# ESP32-C3 register map
Vendor: ESPRESSIF SYSTEMS (SHANGHAI) CO., LTD.; Series: ESP32 C-Series; File version: 19
CPU: RV32IMC r0p0, little endian, no MPU, no FPU, 0 interrupt priority bits
Address unit: 32 bits
Registers are 32-bit, read-write, reset 0x0 unless marked. A register's access mark holds for its fields unless they carry their own. Offsets are from the block's base; [hi:lo] are bit positions; {n}, {i} and the like mark numbered series.

## SENSITIVE — SENSITIVE Peripheral
Base 0x600C1000
0x00 ROM_TABLE_LOCK — SENSITIVE_ROM_TABLE_LOCK_REG
  [0] ROM_TABLE_LOCK
0x04 ROM_TABLE — SENSITIVE_ROM_TABLE_REG
0x08 PRIVILEGE_MODE_SEL_LOCK — SENSITIVE_PRIVILEGE_MODE_SEL_LOCK_REG
  [0] PRIVILEGE_MODE_SEL_LOCK
0x0C PRIVILEGE_MODE_SEL — SENSITIVE_PRIVILEGE_MODE_SEL_REG
  [0] PRIVILEGE_MODE_SEL
0x10 APB_PERIPHERAL_ACCESS_0 — SENSITIVE_APB_PERIPHERAL_ACCESS_0_REG
  [0] APB_PERIPHERAL_ACCESS_LOCK
0x14 APB_PERIPHERAL_ACCESS_1 reset 0x1 — SENSITIVE_APB_PERIPHERAL_ACCESS_1_REG
  [0] APB_PERIPHERAL_ACCESS_SPLIT_BURST
0x18 INTERNAL_SRAM_USAGE_0 — SENSITIVE_INTERNAL_SRAM_USAGE_0_REG
  [0] INTERNAL_SRAM_USAGE_LOCK
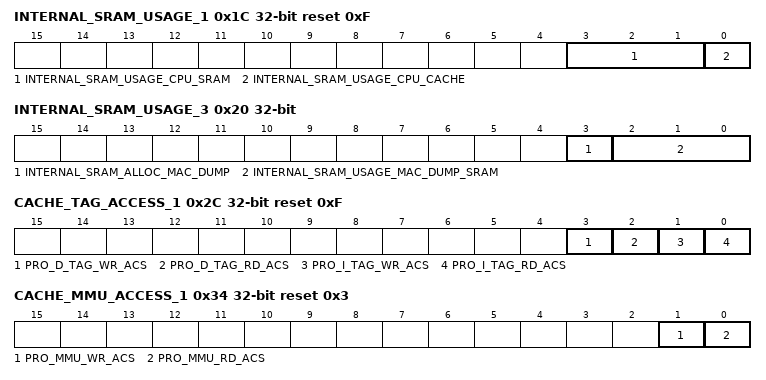
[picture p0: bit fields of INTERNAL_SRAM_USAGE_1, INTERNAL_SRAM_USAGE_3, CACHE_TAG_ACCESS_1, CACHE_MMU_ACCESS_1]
0x1C INTERNAL_SRAM_USAGE_1 reset 0xF — SENSITIVE_INTERNAL_SRAM_USAGE_1_REG
  [3:1] INTERNAL_SRAM_USAGE_CPU_SRAM, [0] INTERNAL_SRAM_USAGE_CPU_CACHE
0x20 INTERNAL_SRAM_USAGE_3 — SENSITIVE_INTERNAL_SRAM_USAGE_3_REG
  [3] INTERNAL_SRAM_ALLOC_MAC_DUMP, [2:0] INTERNAL_SRAM_USAGE_MAC_DUMP_SRAM
0x24 INTERNAL_SRAM_USAGE_4 — SENSITIVE_INTERNAL_SRAM_USAGE_4_REG
  [0] INTERNAL_SRAM_USAGE_LOG_SRAM
0x28 CACHE_TAG_ACCESS_0 — SENSITIVE_CACHE_TAG_ACCESS_0_REG
  [0] CACHE_TAG_ACCESS_LOCK
0x2C CACHE_TAG_ACCESS_1 reset 0xF — SENSITIVE_CACHE_TAG_ACCESS_1_REG
  [3] PRO_D_TAG_WR_ACS, [2] PRO_D_TAG_RD_ACS, [1] PRO_I_TAG_WR_ACS, [0] PRO_I_TAG_RD_ACS
0x30 CACHE_MMU_ACCESS_0 — SENSITIVE_CACHE_MMU_ACCESS_0_REG
  [0] CACHE_MMU_ACCESS_LOCK
0x34 CACHE_MMU_ACCESS_1 reset 0x3 — SENSITIVE_CACHE_MMU_ACCESS_1_REG
  [1] PRO_MMU_WR_ACS, [0] PRO_MMU_RD_ACS
0x38 DMA_APBPERI_SPI2_PMS_CONSTRAIN_0 — SENSITIVE_DMA_APBPERI_SPI2_PMS_CONSTRAIN_0_REG
  [0] DMA_APBPERI_SPI2_PMS_CONSTRAIN_LOCK
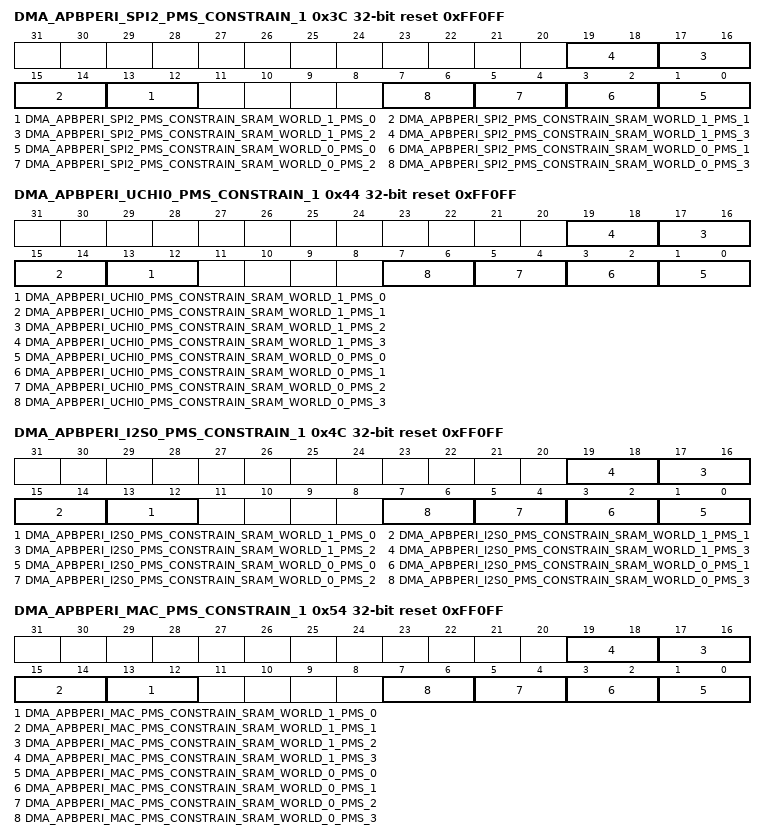
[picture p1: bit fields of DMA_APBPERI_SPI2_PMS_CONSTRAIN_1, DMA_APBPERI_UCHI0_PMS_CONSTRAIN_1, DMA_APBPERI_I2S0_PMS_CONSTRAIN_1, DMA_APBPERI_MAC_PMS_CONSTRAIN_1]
0x3C DMA_APBPERI_SPI2_PMS_CONSTRAIN_1 reset 0xFF0FF — SENSITIVE_DMA_APBPERI_SPI2_PMS_CONSTRAIN_1_REG
  [2n+13:2n+12] DMA_APBPERI_SPI2_PMS_CONSTRAIN_SRAM_WORLD_1_PMS_{n} (n=0..3), [2n+1:2n] DMA_APBPERI_SPI2_PMS_CONSTRAIN_SRAM_WORLD_0_PMS_{n} (n=0..3)
0x40 DMA_APBPERI_UCHI0_PMS_CONSTRAIN_0 — SENSITIVE_DMA_APBPERI_UCHI0_PMS_CONSTRAIN_0_REG
  [0] DMA_APBPERI_UCHI0_PMS_CONSTRAIN_LOCK
0x44 DMA_APBPERI_UCHI0_PMS_CONSTRAIN_1 reset 0xFF0FF — SENSITIVE_DMA_APBPERI_UCHI0_PMS_CONSTRAIN_1_REG
  [2n+13:2n+12] DMA_APBPERI_UCHI0_PMS_CONSTRAIN_SRAM_WORLD_1_PMS_{n} (n=0..3), [2n+1:2n] DMA_APBPERI_UCHI0_PMS_CONSTRAIN_SRAM_WORLD_0_PMS_{n} (n=0..3)
0x48 DMA_APBPERI_I2S0_PMS_CONSTRAIN_0 — SENSITIVE_DMA_APBPERI_I2S0_PMS_CONSTRAIN_0_REG
  [0] DMA_APBPERI_I2S0_PMS_CONSTRAIN_LOCK
0x4C DMA_APBPERI_I2S0_PMS_CONSTRAIN_1 reset 0xFF0FF — SENSITIVE_DMA_APBPERI_I2S0_PMS_CONSTRAIN_1_REG
  [2n+13:2n+12] DMA_APBPERI_I2S0_PMS_CONSTRAIN_SRAM_WORLD_1_PMS_{n} (n=0..3), [2n+1:2n] DMA_APBPERI_I2S0_PMS_CONSTRAIN_SRAM_WORLD_0_PMS_{n} (n=0..3)
0x50 DMA_APBPERI_MAC_PMS_CONSTRAIN_0 — SENSITIVE_DMA_APBPERI_MAC_PMS_CONSTRAIN_0_REG
  [0] DMA_APBPERI_MAC_PMS_CONSTRAIN_LOCK
0x54 DMA_APBPERI_MAC_PMS_CONSTRAIN_1 reset 0xFF0FF — SENSITIVE_DMA_APBPERI_MAC_PMS_CONSTRAIN_1_REG
  [2n+13:2n+12] DMA_APBPERI_MAC_PMS_CONSTRAIN_SRAM_WORLD_1_PMS_{n} (n=0..3), [2n+1:2n] DMA_APBPERI_MAC_PMS_CONSTRAIN_SRAM_WORLD_0_PMS_{n} (n=0..3)
0x58 DMA_APBPERI_BACKUP_PMS_CONSTRAIN_0 — SENSITIVE_DMA_APBPERI_BACKUP_PMS_CONSTRAIN_0_REG
  [0] DMA_APBPERI_BACKUP_PMS_CONSTRAIN_LOCK
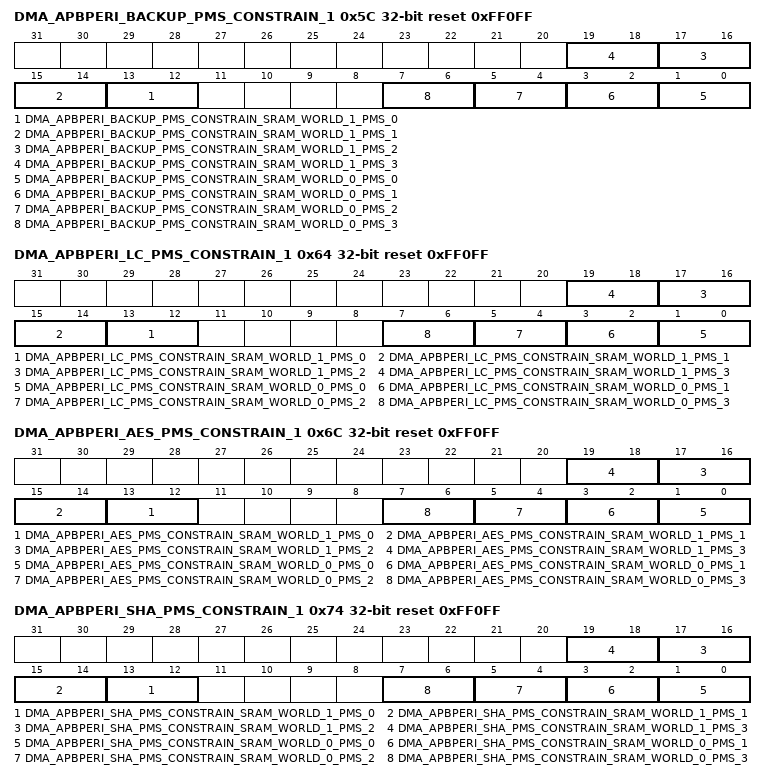
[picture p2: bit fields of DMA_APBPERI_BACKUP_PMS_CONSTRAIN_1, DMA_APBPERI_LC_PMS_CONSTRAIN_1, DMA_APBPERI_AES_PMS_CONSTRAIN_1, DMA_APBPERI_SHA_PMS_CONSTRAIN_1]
0x5C DMA_APBPERI_BACKUP_PMS_CONSTRAIN_1 reset 0xFF0FF — SENSITIVE_DMA_APBPERI_BACKUP_PMS_CONSTRAIN_1_REG
  [2n+13:2n+12] DMA_APBPERI_BACKUP_PMS_CONSTRAIN_SRAM_WORLD_1_PMS_{n} (n=0..3), [2n+1:2n] DMA_APBPERI_BACKUP_PMS_CONSTRAIN_SRAM_WORLD_0_PMS_{n} (n=0..3)
0x60 DMA_APBPERI_LC_PMS_CONSTRAIN_0 — SENSITIVE_DMA_APBPERI_LC_PMS_CONSTRAIN_0_REG
  [0] DMA_APBPERI_LC_PMS_CONSTRAIN_LOCK
0x64 DMA_APBPERI_LC_PMS_CONSTRAIN_1 reset 0xFF0FF — SENSITIVE_DMA_APBPERI_LC_PMS_CONSTRAIN_1_REG
  [2n+13:2n+12] DMA_APBPERI_LC_PMS_CONSTRAIN_SRAM_WORLD_1_PMS_{n} (n=0..3), [2n+1:2n] DMA_APBPERI_LC_PMS_CONSTRAIN_SRAM_WORLD_0_PMS_{n} (n=0..3)
0x68 DMA_APBPERI_AES_PMS_CONSTRAIN_0 — SENSITIVE_DMA_APBPERI_AES_PMS_CONSTRAIN_0_REG
  [0] DMA_APBPERI_AES_PMS_CONSTRAIN_LOCK
0x6C DMA_APBPERI_AES_PMS_CONSTRAIN_1 reset 0xFF0FF — SENSITIVE_DMA_APBPERI_AES_PMS_CONSTRAIN_1_REG
  [2n+13:2n+12] DMA_APBPERI_AES_PMS_CONSTRAIN_SRAM_WORLD_1_PMS_{n} (n=0..3), [2n+1:2n] DMA_APBPERI_AES_PMS_CONSTRAIN_SRAM_WORLD_0_PMS_{n} (n=0..3)
0x70 DMA_APBPERI_SHA_PMS_CONSTRAIN_0 — SENSITIVE_DMA_APBPERI_SHA_PMS_CONSTRAIN_0_REG
  [0] DMA_APBPERI_SHA_PMS_CONSTRAIN_LOCK
0x74 DMA_APBPERI_SHA_PMS_CONSTRAIN_1 reset 0xFF0FF — SENSITIVE_DMA_APBPERI_SHA_PMS_CONSTRAIN_1_REG
  [2n+13:2n+12] DMA_APBPERI_SHA_PMS_CONSTRAIN_SRAM_WORLD_1_PMS_{n} (n=0..3), [2n+1:2n] DMA_APBPERI_SHA_PMS_CONSTRAIN_SRAM_WORLD_0_PMS_{n} (n=0..3)
0x78 DMA_APBPERI_ADC_DAC_PMS_CONSTRAIN_0 — SENSITIVE_DMA_APBPERI_ADC_DAC_PMS_CONSTRAIN_0_REG
  [0] DMA_APBPERI_ADC_DAC_PMS_CONSTRAIN_LOCK
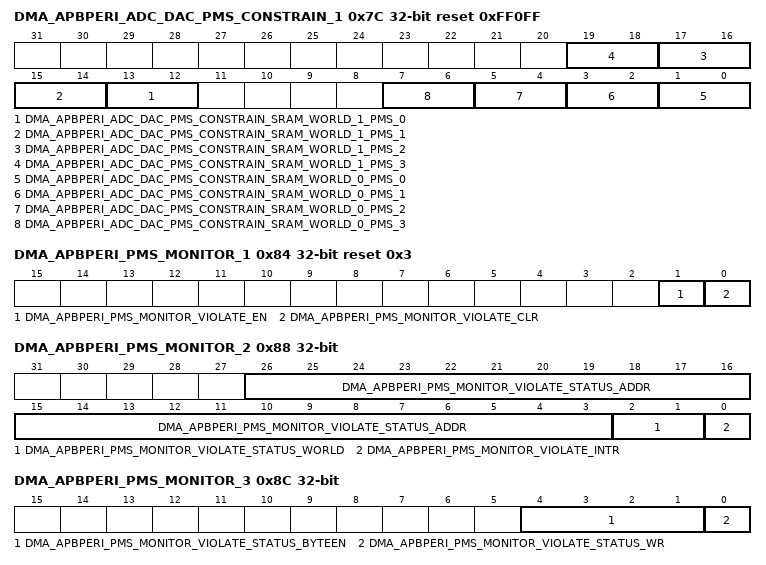
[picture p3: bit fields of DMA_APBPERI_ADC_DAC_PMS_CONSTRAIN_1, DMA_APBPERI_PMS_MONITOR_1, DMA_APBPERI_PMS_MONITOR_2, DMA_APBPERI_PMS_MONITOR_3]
0x7C DMA_APBPERI_ADC_DAC_PMS_CONSTRAIN_1 reset 0xFF0FF — SENSITIVE_DMA_APBPERI_ADC_DAC_PMS_CONSTRAIN_1_REG
  [2n+13:2n+12] DMA_APBPERI_ADC_DAC_PMS_CONSTRAIN_SRAM_WORLD_1_PMS_{n} (n=0..3), [2n+1:2n] DMA_APBPERI_ADC_DAC_PMS_CONSTRAIN_SRAM_WORLD_0_PMS_{n} (n=0..3)
0x80 DMA_APBPERI_PMS_MONITOR_0 — SENSITIVE_DMA_APBPERI_PMS_MONITOR_0_REG
  [0] DMA_APBPERI_PMS_MONITOR_LOCK
0x84 DMA_APBPERI_PMS_MONITOR_1 reset 0x3 — SENSITIVE_DMA_APBPERI_PMS_MONITOR_1_REG
  [1] DMA_APBPERI_PMS_MONITOR_VIOLATE_EN, [0] DMA_APBPERI_PMS_MONITOR_VIOLATE_CLR
0x88 DMA_APBPERI_PMS_MONITOR_2 ro — SENSITIVE_DMA_APBPERI_PMS_MONITOR_2_REG
  [26:3] DMA_APBPERI_PMS_MONITOR_VIOLATE_STATUS_ADDR, [2:1] DMA_APBPERI_PMS_MONITOR_VIOLATE_STATUS_WORLD, [0] DMA_APBPERI_PMS_MONITOR_VIOLATE_INTR
0x8C DMA_APBPERI_PMS_MONITOR_3 ro — SENSITIVE_DMA_APBPERI_PMS_MONITOR_3_REG
  [4:1] DMA_APBPERI_PMS_MONITOR_VIOLATE_STATUS_BYTEEN, [0] DMA_APBPERI_PMS_MONITOR_VIOLATE_STATUS_WR
0x90 CORE_X_IRAM0_DRAM0_DMA_SPLIT_LINE_CONSTRAIN_0 — SENSITIVE_CORE_X_IRAM0_DRAM0_DMA_SPLIT_LINE_CONSTRAIN_0_REG
  [0] CORE_X_IRAM0_DRAM0_DMA_SPLIT_LINE_CONSTRAIN_LOCK
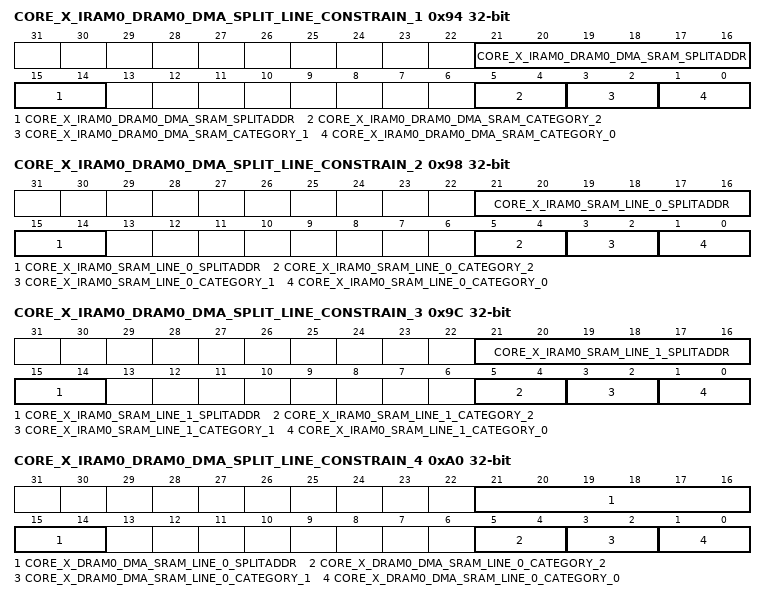
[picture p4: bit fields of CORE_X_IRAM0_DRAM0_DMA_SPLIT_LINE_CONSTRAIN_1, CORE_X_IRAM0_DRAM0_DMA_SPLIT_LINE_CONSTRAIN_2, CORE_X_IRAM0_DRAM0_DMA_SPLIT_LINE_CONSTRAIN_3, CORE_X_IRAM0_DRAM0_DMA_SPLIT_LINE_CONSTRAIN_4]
0x94 CORE_X_IRAM0_DRAM0_DMA_SPLIT_LINE_CONSTRAIN_1 — SENSITIVE_CORE_X_IRAM0_DRAM0_DMA_SPLIT_LINE_CONSTRAIN_1_REG
  [21:14] CORE_X_IRAM0_DRAM0_DMA_SRAM_SPLITADDR, [5:4] CORE_X_IRAM0_DRAM0_DMA_SRAM_CATEGORY_2, [3:2] CORE_X_IRAM0_DRAM0_DMA_SRAM_CATEGORY_1, [1:0] CORE_X_IRAM0_DRAM0_DMA_SRAM_CATEGORY_0
0x98 CORE_X_IRAM0_DRAM0_DMA_SPLIT_LINE_CONSTRAIN_2 — SENSITIVE_CORE_X_IRAM0_DRAM0_DMA_SPLIT_LINE_CONSTRAIN_2_REG
  [21:14] CORE_X_IRAM0_SRAM_LINE_0_SPLITADDR, [5:4] CORE_X_IRAM0_SRAM_LINE_0_CATEGORY_2, [3:2] CORE_X_IRAM0_SRAM_LINE_0_CATEGORY_1, [1:0] CORE_X_IRAM0_SRAM_LINE_0_CATEGORY_0
0x9C CORE_X_IRAM0_DRAM0_DMA_SPLIT_LINE_CONSTRAIN_3 — SENSITIVE_CORE_X_IRAM0_DRAM0_DMA_SPLIT_LINE_CONSTRAIN_3_REG
  [21:14] CORE_X_IRAM0_SRAM_LINE_1_SPLITADDR, [5:4] CORE_X_IRAM0_SRAM_LINE_1_CATEGORY_2, [3:2] CORE_X_IRAM0_SRAM_LINE_1_CATEGORY_1, [1:0] CORE_X_IRAM0_SRAM_LINE_1_CATEGORY_0
0xA0 CORE_X_IRAM0_DRAM0_DMA_SPLIT_LINE_CONSTRAIN_4 — SENSITIVE_CORE_X_IRAM0_DRAM0_DMA_SPLIT_LINE_CONSTRAIN_4_REG
  [21:14] CORE_X_DRAM0_DMA_SRAM_LINE_0_SPLITADDR, [5:4] CORE_X_DRAM0_DMA_SRAM_LINE_0_CATEGORY_2, [3:2] CORE_X_DRAM0_DMA_SRAM_LINE_0_CATEGORY_1, [1:0] CORE_X_DRAM0_DMA_SRAM_LINE_0_CATEGORY_0
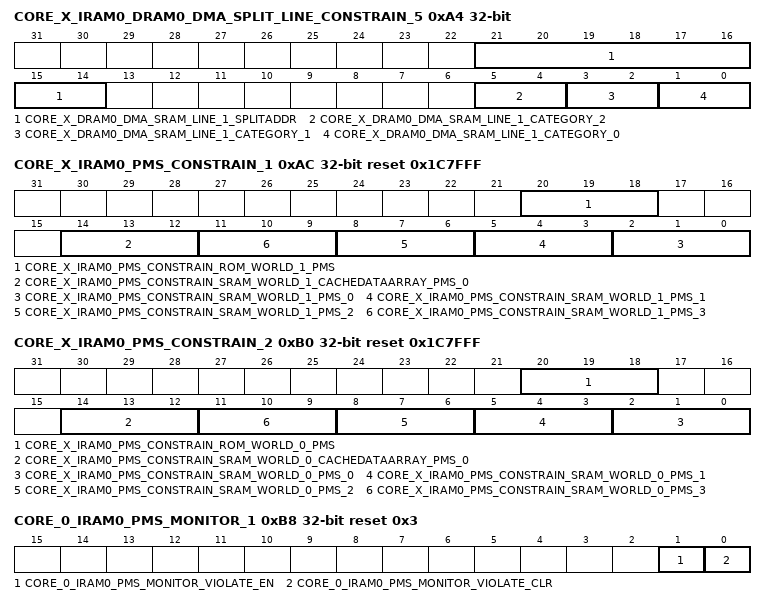
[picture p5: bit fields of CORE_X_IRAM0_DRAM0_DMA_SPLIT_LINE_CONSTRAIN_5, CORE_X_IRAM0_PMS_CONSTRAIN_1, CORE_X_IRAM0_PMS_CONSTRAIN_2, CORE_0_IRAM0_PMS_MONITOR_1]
0xA4 CORE_X_IRAM0_DRAM0_DMA_SPLIT_LINE_CONSTRAIN_5 — SENSITIVE_CORE_X_IRAM0_DRAM0_DMA_SPLIT_LINE_CONSTRAIN_5_REG
  [21:14] CORE_X_DRAM0_DMA_SRAM_LINE_1_SPLITADDR, [5:4] CORE_X_DRAM0_DMA_SRAM_LINE_1_CATEGORY_2, [3:2] CORE_X_DRAM0_DMA_SRAM_LINE_1_CATEGORY_1, [1:0] CORE_X_DRAM0_DMA_SRAM_LINE_1_CATEGORY_0
0xA8 CORE_X_IRAM0_PMS_CONSTRAIN_0 — SENSITIVE_CORE_X_IRAM0_PMS_CONSTRAIN_0_REG
  [0] CORE_X_IRAM0_PMS_CONSTRAIN_LOCK
0xAC CORE_X_IRAM0_PMS_CONSTRAIN_1 reset 0x1C7FFF — SENSITIVE_CORE_X_IRAM0_PMS_CONSTRAIN_1_REG
  [20:18] CORE_X_IRAM0_PMS_CONSTRAIN_ROM_WORLD_1_PMS, [14:12] CORE_X_IRAM0_PMS_CONSTRAIN_SRAM_WORLD_1_CACHEDATAARRAY_PMS_0, [3n+2:3n] CORE_X_IRAM0_PMS_CONSTRAIN_SRAM_WORLD_1_PMS_{n} (n=0..3)
0xB0 CORE_X_IRAM0_PMS_CONSTRAIN_2 reset 0x1C7FFF — SENSITIVE_CORE_X_IRAM0_PMS_CONSTRAIN_2_REG
  [20:18] CORE_X_IRAM0_PMS_CONSTRAIN_ROM_WORLD_0_PMS, [14:12] CORE_X_IRAM0_PMS_CONSTRAIN_SRAM_WORLD_0_CACHEDATAARRAY_PMS_0, [3n+2:3n] CORE_X_IRAM0_PMS_CONSTRAIN_SRAM_WORLD_0_PMS_{n} (n=0..3)
0xB4 CORE_0_IRAM0_PMS_MONITOR_0 — SENSITIVE_CORE_0_IRAM0_PMS_MONITOR_0_REG
  [0] CORE_0_IRAM0_PMS_MONITOR_LOCK
0xB8 CORE_0_IRAM0_PMS_MONITOR_1 reset 0x3 — SENSITIVE_CORE_0_IRAM0_PMS_MONITOR_1_REG
  [1] CORE_0_IRAM0_PMS_MONITOR_VIOLATE_EN, [0] CORE_0_IRAM0_PMS_MONITOR_VIOLATE_CLR
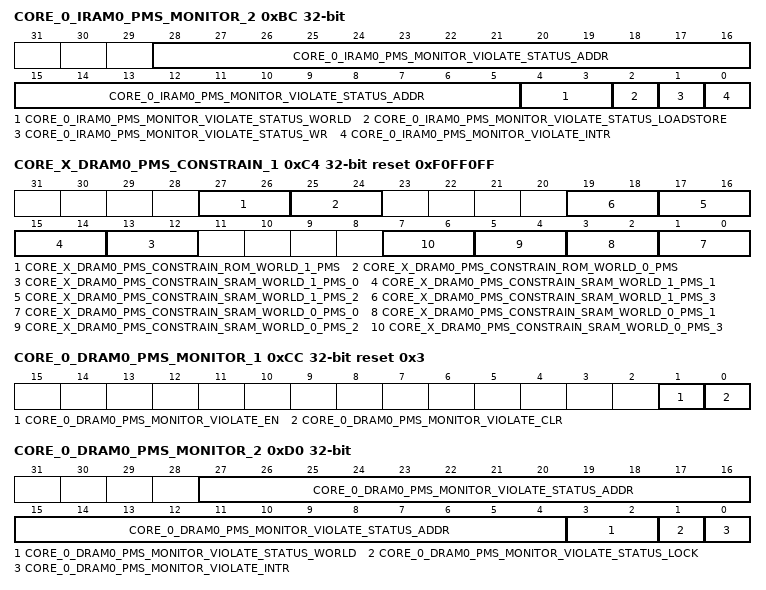
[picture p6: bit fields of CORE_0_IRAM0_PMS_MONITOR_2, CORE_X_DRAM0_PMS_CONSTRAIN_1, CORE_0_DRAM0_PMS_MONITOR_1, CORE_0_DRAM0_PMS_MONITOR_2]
0xBC CORE_0_IRAM0_PMS_MONITOR_2 ro — SENSITIVE_CORE_0_IRAM0_PMS_MONITOR_2_REG
  [28:5] CORE_0_IRAM0_PMS_MONITOR_VIOLATE_STATUS_ADDR, [4:3] CORE_0_IRAM0_PMS_MONITOR_VIOLATE_STATUS_WORLD, [2] CORE_0_IRAM0_PMS_MONITOR_VIOLATE_STATUS_LOADSTORE, [1] CORE_0_IRAM0_PMS_MONITOR_VIOLATE_STATUS_WR, [0] CORE_0_IRAM0_PMS_MONITOR_VIOLATE_INTR
0xC0 CORE_X_DRAM0_PMS_CONSTRAIN_0 — SENSITIVE_CORE_X_DRAM0_PMS_CONSTRAIN_0_REG
  [0] CORE_X_DRAM0_PMS_CONSTRAIN_LOCK
0xC4 CORE_X_DRAM0_PMS_CONSTRAIN_1 reset 0xF0FF0FF — SENSITIVE_CORE_X_DRAM0_PMS_CONSTRAIN_1_REG
  [27:26] CORE_X_DRAM0_PMS_CONSTRAIN_ROM_WORLD_1_PMS, [25:24] CORE_X_DRAM0_PMS_CONSTRAIN_ROM_WORLD_0_PMS, [2n+13:2n+12] CORE_X_DRAM0_PMS_CONSTRAIN_SRAM_WORLD_1_PMS_{n} (n=0..3), [2n+1:2n] CORE_X_DRAM0_PMS_CONSTRAIN_SRAM_WORLD_0_PMS_{n} (n=0..3)
0xC8 CORE_0_DRAM0_PMS_MONITOR_0 — SENSITIVE_CORE_0_DRAM0_PMS_MONITOR_0_REG
  [0] CORE_0_DRAM0_PMS_MONITOR_LOCK
0xCC CORE_0_DRAM0_PMS_MONITOR_1 reset 0x3 — SENSITIVE_CORE_0_DRAM0_PMS_MONITOR_1_REG
  [1] CORE_0_DRAM0_PMS_MONITOR_VIOLATE_EN, [0] CORE_0_DRAM0_PMS_MONITOR_VIOLATE_CLR
0xD0 CORE_0_DRAM0_PMS_MONITOR_2 ro — SENSITIVE_CORE_0_DRAM0_PMS_MONITOR_2_REG
  [27:4] CORE_0_DRAM0_PMS_MONITOR_VIOLATE_STATUS_ADDR, [3:2] CORE_0_DRAM0_PMS_MONITOR_VIOLATE_STATUS_WORLD, [1] CORE_0_DRAM0_PMS_MONITOR_VIOLATE_STATUS_LOCK, [0] CORE_0_DRAM0_PMS_MONITOR_VIOLATE_INTR
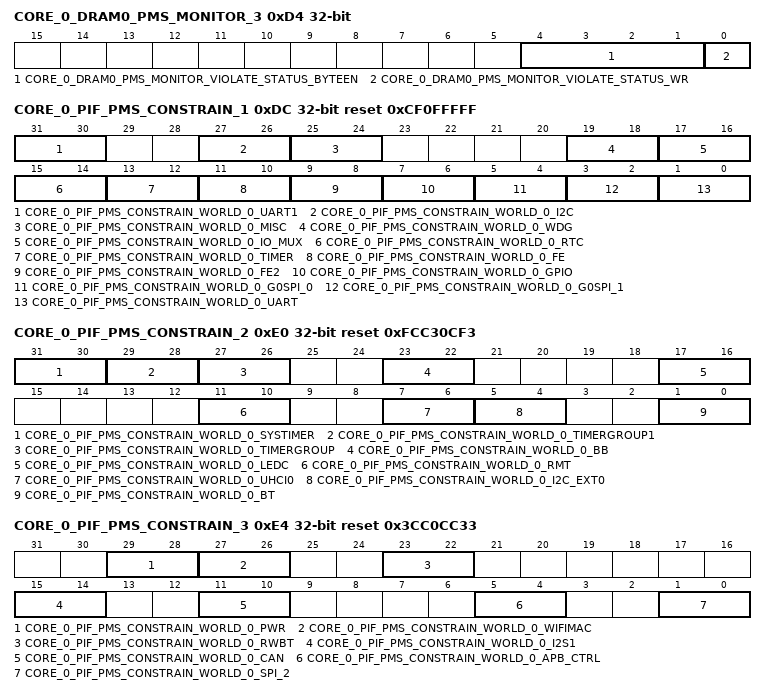
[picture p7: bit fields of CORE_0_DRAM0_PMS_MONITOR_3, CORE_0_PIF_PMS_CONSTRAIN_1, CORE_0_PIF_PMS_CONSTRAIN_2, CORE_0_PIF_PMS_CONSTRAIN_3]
0xD4 CORE_0_DRAM0_PMS_MONITOR_3 ro — SENSITIVE_CORE_0_DRAM0_PMS_MONITOR_3_REG
  [4:1] CORE_0_DRAM0_PMS_MONITOR_VIOLATE_STATUS_BYTEEN, [0] CORE_0_DRAM0_PMS_MONITOR_VIOLATE_STATUS_WR
0xD8 CORE_0_PIF_PMS_CONSTRAIN_0 — SENSITIVE_CORE_0_PIF_PMS_CONSTRAIN_0_REG
  [0] CORE_0_PIF_PMS_CONSTRAIN_LOCK
0xDC CORE_0_PIF_PMS_CONSTRAIN_1 reset 0xCF0FFFFF — SENSITIVE_CORE_0_PIF_PMS_CONSTRAIN_1_REG
  [31:30] CORE_0_PIF_PMS_CONSTRAIN_WORLD_0_UART1, [27:26] CORE_0_PIF_PMS_CONSTRAIN_WORLD_0_I2C, [25:24] CORE_0_PIF_PMS_CONSTRAIN_WORLD_0_MISC, [19:18] CORE_0_PIF_PMS_CONSTRAIN_WORLD_0_WDG, [17:16] CORE_0_PIF_PMS_CONSTRAIN_WORLD_0_IO_MUX, [15:14] CORE_0_PIF_PMS_CONSTRAIN_WORLD_0_RTC, [13:12] CORE_0_PIF_PMS_CONSTRAIN_WORLD_0_TIMER, [11:10] CORE_0_PIF_PMS_CONSTRAIN_WORLD_0_FE, [9:8] CORE_0_PIF_PMS_CONSTRAIN_WORLD_0_FE2, [7:6] CORE_0_PIF_PMS_CONSTRAIN_WORLD_0_GPIO, [5:4] CORE_0_PIF_PMS_CONSTRAIN_WORLD_0_G0SPI_0, [3:2] CORE_0_PIF_PMS_CONSTRAIN_WORLD_0_G0SPI_1, [1:0] CORE_0_PIF_PMS_CONSTRAIN_WORLD_0_UART
0xE0 CORE_0_PIF_PMS_CONSTRAIN_2 reset 0xFCC30CF3 — SENSITIVE_CORE_0_PIF_PMS_CONSTRAIN_2_REG
  [31:30] CORE_0_PIF_PMS_CONSTRAIN_WORLD_0_SYSTIMER, [29:28] CORE_0_PIF_PMS_CONSTRAIN_WORLD_0_TIMERGROUP1, [27:26] CORE_0_PIF_PMS_CONSTRAIN_WORLD_0_TIMERGROUP, [23:22] CORE_0_PIF_PMS_CONSTRAIN_WORLD_0_BB, [17:16] CORE_0_PIF_PMS_CONSTRAIN_WORLD_0_LEDC, [11:10] CORE_0_PIF_PMS_CONSTRAIN_WORLD_0_RMT, [7:6] CORE_0_PIF_PMS_CONSTRAIN_WORLD_0_UHCI0, [5:4] CORE_0_PIF_PMS_CONSTRAIN_WORLD_0_I2C_EXT0, [1:0] CORE_0_PIF_PMS_CONSTRAIN_WORLD_0_BT
0xE4 CORE_0_PIF_PMS_CONSTRAIN_3 reset 0x3CC0CC33 — SENSITIVE_CORE_0_PIF_PMS_CONSTRAIN_3_REG
  [29:28] CORE_0_PIF_PMS_CONSTRAIN_WORLD_0_PWR, [27:26] CORE_0_PIF_PMS_CONSTRAIN_WORLD_0_WIFIMAC, [23:22] CORE_0_PIF_PMS_CONSTRAIN_WORLD_0_RWBT, [15:14] CORE_0_PIF_PMS_CONSTRAIN_WORLD_0_I2S1, [11:10] CORE_0_PIF_PMS_CONSTRAIN_WORLD_0_CAN, [5:4] CORE_0_PIF_PMS_CONSTRAIN_WORLD_0_APB_CTRL, [1:0] CORE_0_PIF_PMS_CONSTRAIN_WORLD_0_SPI_2
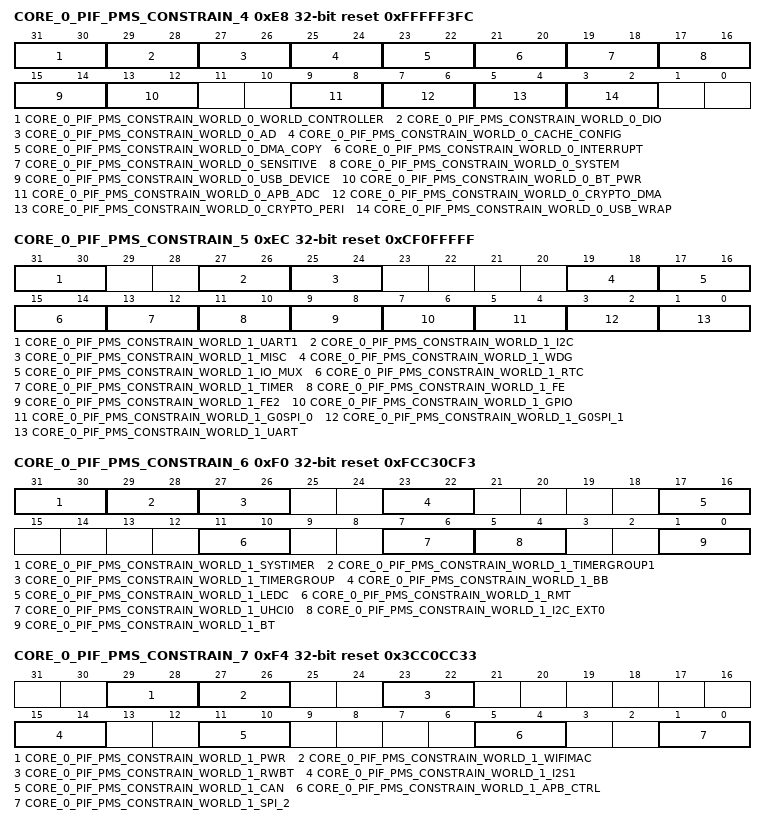
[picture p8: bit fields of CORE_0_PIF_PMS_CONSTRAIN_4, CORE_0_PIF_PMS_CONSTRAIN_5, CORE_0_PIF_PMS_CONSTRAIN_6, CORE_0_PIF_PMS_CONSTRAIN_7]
0xE8 CORE_0_PIF_PMS_CONSTRAIN_4 reset 0xFFFFF3FC — SENSITIVE_CORE_0_PIF_PMS_CONSTRAIN_4_REG
  [31:30] CORE_0_PIF_PMS_CONSTRAIN_WORLD_0_WORLD_CONTROLLER, [29:28] CORE_0_PIF_PMS_CONSTRAIN_WORLD_0_DIO, [27:26] CORE_0_PIF_PMS_CONSTRAIN_WORLD_0_AD, [25:24] CORE_0_PIF_PMS_CONSTRAIN_WORLD_0_CACHE_CONFIG, [23:22] CORE_0_PIF_PMS_CONSTRAIN_WORLD_0_DMA_COPY, [21:20] CORE_0_PIF_PMS_CONSTRAIN_WORLD_0_INTERRUPT, [19:18] CORE_0_PIF_PMS_CONSTRAIN_WORLD_0_SENSITIVE, [17:16] CORE_0_PIF_PMS_CONSTRAIN_WORLD_0_SYSTEM, [15:14] CORE_0_PIF_PMS_CONSTRAIN_WORLD_0_USB_DEVICE, [13:12] CORE_0_PIF_PMS_CONSTRAIN_WORLD_0_BT_PWR, [9:8] CORE_0_PIF_PMS_CONSTRAIN_WORLD_0_APB_ADC, [7:6] CORE_0_PIF_PMS_CONSTRAIN_WORLD_0_CRYPTO_DMA, [5:4] CORE_0_PIF_PMS_CONSTRAIN_WORLD_0_CRYPTO_PERI, [3:2] CORE_0_PIF_PMS_CONSTRAIN_WORLD_0_USB_WRAP
0xEC CORE_0_PIF_PMS_CONSTRAIN_5 reset 0xCF0FFFFF — SENSITIVE_CORE_0_PIF_PMS_CONSTRAIN_5_REG
  [31:30] CORE_0_PIF_PMS_CONSTRAIN_WORLD_1_UART1, [27:26] CORE_0_PIF_PMS_CONSTRAIN_WORLD_1_I2C, [25:24] CORE_0_PIF_PMS_CONSTRAIN_WORLD_1_MISC, [19:18] CORE_0_PIF_PMS_CONSTRAIN_WORLD_1_WDG, [17:16] CORE_0_PIF_PMS_CONSTRAIN_WORLD_1_IO_MUX, [15:14] CORE_0_PIF_PMS_CONSTRAIN_WORLD_1_RTC, [13:12] CORE_0_PIF_PMS_CONSTRAIN_WORLD_1_TIMER, [11:10] CORE_0_PIF_PMS_CONSTRAIN_WORLD_1_FE, [9:8] CORE_0_PIF_PMS_CONSTRAIN_WORLD_1_FE2, [7:6] CORE_0_PIF_PMS_CONSTRAIN_WORLD_1_GPIO, [5:4] CORE_0_PIF_PMS_CONSTRAIN_WORLD_1_G0SPI_0, [3:2] CORE_0_PIF_PMS_CONSTRAIN_WORLD_1_G0SPI_1, [1:0] CORE_0_PIF_PMS_CONSTRAIN_WORLD_1_UART
0xF0 CORE_0_PIF_PMS_CONSTRAIN_6 reset 0xFCC30CF3 — SENSITIVE_CORE_0_PIF_PMS_CONSTRAIN_6_REG
  [31:30] CORE_0_PIF_PMS_CONSTRAIN_WORLD_1_SYSTIMER, [29:28] CORE_0_PIF_PMS_CONSTRAIN_WORLD_1_TIMERGROUP1, [27:26] CORE_0_PIF_PMS_CONSTRAIN_WORLD_1_TIMERGROUP, [23:22] CORE_0_PIF_PMS_CONSTRAIN_WORLD_1_BB, [17:16] CORE_0_PIF_PMS_CONSTRAIN_WORLD_1_LEDC, [11:10] CORE_0_PIF_PMS_CONSTRAIN_WORLD_1_RMT, [7:6] CORE_0_PIF_PMS_CONSTRAIN_WORLD_1_UHCI0, [5:4] CORE_0_PIF_PMS_CONSTRAIN_WORLD_1_I2C_EXT0, [1:0] CORE_0_PIF_PMS_CONSTRAIN_WORLD_1_BT
0xF4 CORE_0_PIF_PMS_CONSTRAIN_7 reset 0x3CC0CC33 — SENSITIVE_CORE_0_PIF_PMS_CONSTRAIN_7_REG
  [29:28] CORE_0_PIF_PMS_CONSTRAIN_WORLD_1_PWR, [27:26] CORE_0_PIF_PMS_CONSTRAIN_WORLD_1_WIFIMAC, [23:22] CORE_0_PIF_PMS_CONSTRAIN_WORLD_1_RWBT, [15:14] CORE_0_PIF_PMS_CONSTRAIN_WORLD_1_I2S1, [11:10] CORE_0_PIF_PMS_CONSTRAIN_WORLD_1_CAN, [5:4] CORE_0_PIF_PMS_CONSTRAIN_WORLD_1_APB_CTRL, [1:0] CORE_0_PIF_PMS_CONSTRAIN_WORLD_1_SPI_2
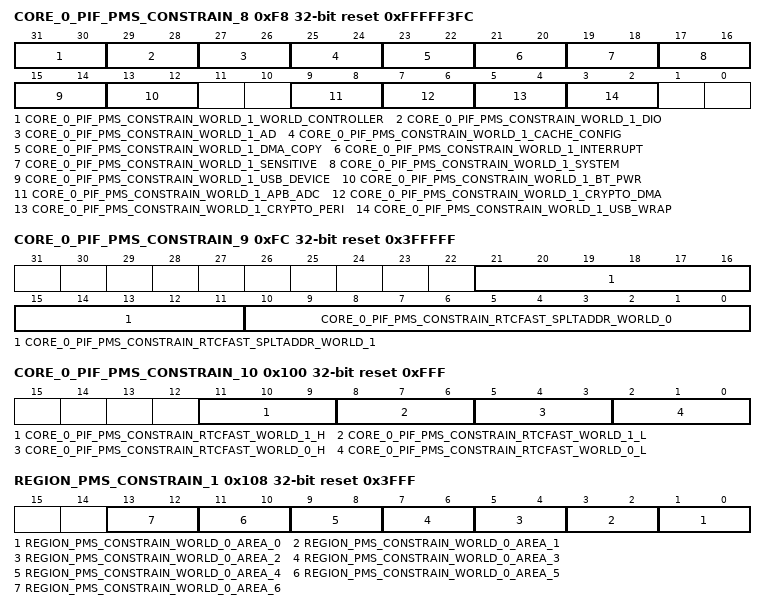
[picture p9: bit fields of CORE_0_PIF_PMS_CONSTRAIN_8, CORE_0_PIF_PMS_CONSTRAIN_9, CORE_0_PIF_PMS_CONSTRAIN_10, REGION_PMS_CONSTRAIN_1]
0xF8 CORE_0_PIF_PMS_CONSTRAIN_8 reset 0xFFFFF3FC — SENSITIVE_CORE_0_PIF_PMS_CONSTRAIN_8_REG
  [31:30] CORE_0_PIF_PMS_CONSTRAIN_WORLD_1_WORLD_CONTROLLER, [29:28] CORE_0_PIF_PMS_CONSTRAIN_WORLD_1_DIO, [27:26] CORE_0_PIF_PMS_CONSTRAIN_WORLD_1_AD, [25:24] CORE_0_PIF_PMS_CONSTRAIN_WORLD_1_CACHE_CONFIG, [23:22] CORE_0_PIF_PMS_CONSTRAIN_WORLD_1_DMA_COPY, [21:20] CORE_0_PIF_PMS_CONSTRAIN_WORLD_1_INTERRUPT, [19:18] CORE_0_PIF_PMS_CONSTRAIN_WORLD_1_SENSITIVE, [17:16] CORE_0_PIF_PMS_CONSTRAIN_WORLD_1_SYSTEM, [15:14] CORE_0_PIF_PMS_CONSTRAIN_WORLD_1_USB_DEVICE, [13:12] CORE_0_PIF_PMS_CONSTRAIN_WORLD_1_BT_PWR, [9:8] CORE_0_PIF_PMS_CONSTRAIN_WORLD_1_APB_ADC, [7:6] CORE_0_PIF_PMS_CONSTRAIN_WORLD_1_CRYPTO_DMA, [5:4] CORE_0_PIF_PMS_CONSTRAIN_WORLD_1_CRYPTO_PERI, [3:2] CORE_0_PIF_PMS_CONSTRAIN_WORLD_1_USB_WRAP
0xFC CORE_0_PIF_PMS_CONSTRAIN_9 reset 0x3FFFFF — SENSITIVE_CORE_0_PIF_PMS_CONSTRAIN_9_REG
  [21:11] CORE_0_PIF_PMS_CONSTRAIN_RTCFAST_SPLTADDR_WORLD_1, [10:0] CORE_0_PIF_PMS_CONSTRAIN_RTCFAST_SPLTADDR_WORLD_0
0x100 CORE_0_PIF_PMS_CONSTRAIN_10 reset 0xFFF — SENSITIVE_CORE_0_PIF_PMS_CONSTRAIN_10_REG
  [11:9] CORE_0_PIF_PMS_CONSTRAIN_RTCFAST_WORLD_1_H, [8:6] CORE_0_PIF_PMS_CONSTRAIN_RTCFAST_WORLD_1_L, [5:3] CORE_0_PIF_PMS_CONSTRAIN_RTCFAST_WORLD_0_H, [2:0] CORE_0_PIF_PMS_CONSTRAIN_RTCFAST_WORLD_0_L
0x104 REGION_PMS_CONSTRAIN_0 — SENSITIVE_REGION_PMS_CONSTRAIN_0_REG
  [0] REGION_PMS_CONSTRAIN_LOCK
0x108 REGION_PMS_CONSTRAIN_1 reset 0x3FFF — SENSITIVE_REGION_PMS_CONSTRAIN_1_REG
  [2n+1:2n] REGION_PMS_CONSTRAIN_WORLD_0_AREA_{n} (n=0..6)
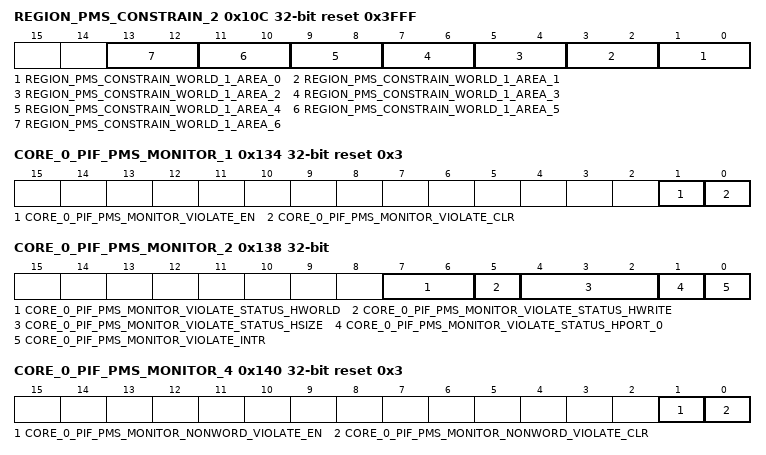
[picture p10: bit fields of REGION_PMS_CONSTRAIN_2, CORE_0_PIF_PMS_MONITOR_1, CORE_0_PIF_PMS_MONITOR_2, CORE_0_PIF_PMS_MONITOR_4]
0x10C REGION_PMS_CONSTRAIN_2 reset 0x3FFF — SENSITIVE_REGION_PMS_CONSTRAIN_2_REG
  [2n+1:2n] REGION_PMS_CONSTRAIN_WORLD_1_AREA_{n} (n=0..6)
{0x104+4i} REGION_PMS_CONSTRAIN_{i} (i=3..10) — SENSITIVE_REGION_PMS_CONSTRAIN_{i}_REG
  [29:0] REGION_PMS_CONSTRAIN_ADDR_{i-3}
0x130 CORE_0_PIF_PMS_MONITOR_0 — SENSITIVE_CORE_0_PIF_PMS_MONITOR_0_REG
  [0] CORE_0_PIF_PMS_MONITOR_LOCK
0x134 CORE_0_PIF_PMS_MONITOR_1 reset 0x3 — SENSITIVE_CORE_0_PIF_PMS_MONITOR_1_REG
  [1] CORE_0_PIF_PMS_MONITOR_VIOLATE_EN, [0] CORE_0_PIF_PMS_MONITOR_VIOLATE_CLR
0x138 CORE_0_PIF_PMS_MONITOR_2 ro — SENSITIVE_CORE_0_PIF_PMS_MONITOR_2_REG
  [7:6] CORE_0_PIF_PMS_MONITOR_VIOLATE_STATUS_HWORLD, [5] CORE_0_PIF_PMS_MONITOR_VIOLATE_STATUS_HWRITE, [4:2] CORE_0_PIF_PMS_MONITOR_VIOLATE_STATUS_HSIZE, [1] CORE_0_PIF_PMS_MONITOR_VIOLATE_STATUS_HPORT_0, [0] CORE_0_PIF_PMS_MONITOR_VIOLATE_INTR
0x13C CORE_0_PIF_PMS_MONITOR_3 ro — SENSITIVE_CORE_0_PIF_PMS_MONITOR_3_REG
  [31:0] CORE_0_PIF_PMS_MONITOR_VIOLATE_STATUS_HADDR
0x140 CORE_0_PIF_PMS_MONITOR_4 reset 0x3 — SENSITIVE_CORE_0_PIF_PMS_MONITOR_4_REG
  [1] CORE_0_PIF_PMS_MONITOR_NONWORD_VIOLATE_EN, [0] CORE_0_PIF_PMS_MONITOR_NONWORD_VIOLATE_CLR
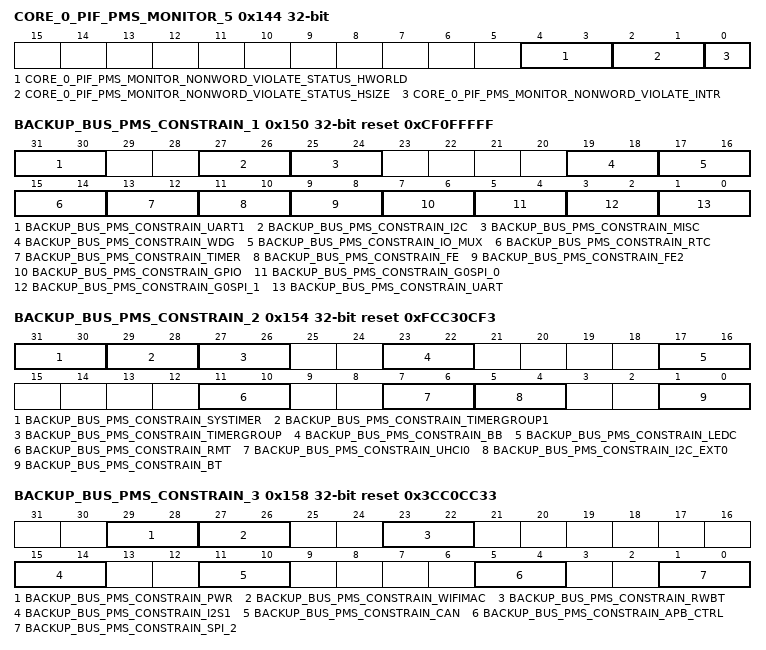
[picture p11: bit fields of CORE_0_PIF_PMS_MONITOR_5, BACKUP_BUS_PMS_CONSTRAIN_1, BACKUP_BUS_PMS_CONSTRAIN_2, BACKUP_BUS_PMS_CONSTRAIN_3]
0x144 CORE_0_PIF_PMS_MONITOR_5 ro — SENSITIVE_CORE_0_PIF_PMS_MONITOR_5_REG
  [4:3] CORE_0_PIF_PMS_MONITOR_NONWORD_VIOLATE_STATUS_HWORLD, [2:1] CORE_0_PIF_PMS_MONITOR_NONWORD_VIOLATE_STATUS_HSIZE, [0] CORE_0_PIF_PMS_MONITOR_NONWORD_VIOLATE_INTR
0x148 CORE_0_PIF_PMS_MONITOR_6 ro — SENSITIVE_CORE_0_PIF_PMS_MONITOR_6_REG
  [31:0] CORE_0_PIF_PMS_MONITOR_NONWORD_VIOLATE_STATUS_HADDR
0x14C BACKUP_BUS_PMS_CONSTRAIN_0 — SENSITIVE_BACKUP_BUS_PMS_CONSTRAIN_0_REG
  [0] BACKUP_BUS_PMS_CONSTRAIN_LOCK
0x150 BACKUP_BUS_PMS_CONSTRAIN_1 reset 0xCF0FFFFF — SENSITIVE_BACKUP_BUS_PMS_CONSTRAIN_1_REG
  [31:30] BACKUP_BUS_PMS_CONSTRAIN_UART1, [27:26] BACKUP_BUS_PMS_CONSTRAIN_I2C, [25:24] BACKUP_BUS_PMS_CONSTRAIN_MISC, [19:18] BACKUP_BUS_PMS_CONSTRAIN_WDG, [17:16] BACKUP_BUS_PMS_CONSTRAIN_IO_MUX, [15:14] BACKUP_BUS_PMS_CONSTRAIN_RTC, [13:12] BACKUP_BUS_PMS_CONSTRAIN_TIMER, [11:10] BACKUP_BUS_PMS_CONSTRAIN_FE, [9:8] BACKUP_BUS_PMS_CONSTRAIN_FE2, [7:6] BACKUP_BUS_PMS_CONSTRAIN_GPIO, [5:4] BACKUP_BUS_PMS_CONSTRAIN_G0SPI_0, [3:2] BACKUP_BUS_PMS_CONSTRAIN_G0SPI_1, [1:0] BACKUP_BUS_PMS_CONSTRAIN_UART
0x154 BACKUP_BUS_PMS_CONSTRAIN_2 reset 0xFCC30CF3 — SENSITIVE_BACKUP_BUS_PMS_CONSTRAIN_2_REG
  [31:30] BACKUP_BUS_PMS_CONSTRAIN_SYSTIMER, [29:28] BACKUP_BUS_PMS_CONSTRAIN_TIMERGROUP1, [27:26] BACKUP_BUS_PMS_CONSTRAIN_TIMERGROUP, [23:22] BACKUP_BUS_PMS_CONSTRAIN_BB, [17:16] BACKUP_BUS_PMS_CONSTRAIN_LEDC, [11:10] BACKUP_BUS_PMS_CONSTRAIN_RMT, [7:6] BACKUP_BUS_PMS_CONSTRAIN_UHCI0, [5:4] BACKUP_BUS_PMS_CONSTRAIN_I2C_EXT0, [1:0] BACKUP_BUS_PMS_CONSTRAIN_BT
0x158 BACKUP_BUS_PMS_CONSTRAIN_3 reset 0x3CC0CC33 — SENSITIVE_BACKUP_BUS_PMS_CONSTRAIN_3_REG
  [29:28] BACKUP_BUS_PMS_CONSTRAIN_PWR, [27:26] BACKUP_BUS_PMS_CONSTRAIN_WIFIMAC, [23:22] BACKUP_BUS_PMS_CONSTRAIN_RWBT, [15:14] BACKUP_BUS_PMS_CONSTRAIN_I2S1, [11:10] BACKUP_BUS_PMS_CONSTRAIN_CAN, [5:4] BACKUP_BUS_PMS_CONSTRAIN_APB_CTRL, [1:0] BACKUP_BUS_PMS_CONSTRAIN_SPI_2
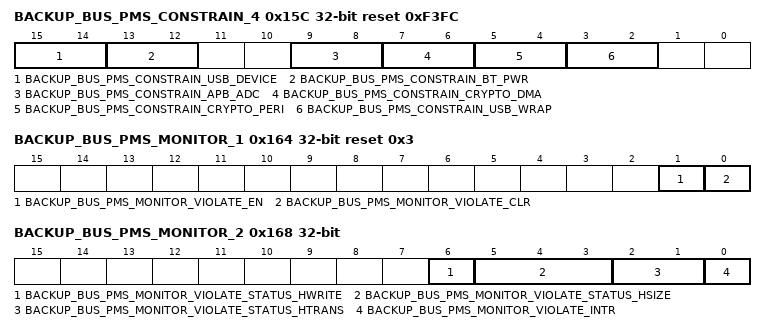
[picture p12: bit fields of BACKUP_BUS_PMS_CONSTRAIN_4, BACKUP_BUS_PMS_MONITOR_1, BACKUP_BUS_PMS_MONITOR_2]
0x15C BACKUP_BUS_PMS_CONSTRAIN_4 reset 0xF3FC — SENSITIVE_BACKUP_BUS_PMS_CONSTRAIN_4_REG
  [15:14] BACKUP_BUS_PMS_CONSTRAIN_USB_DEVICE, [13:12] BACKUP_BUS_PMS_CONSTRAIN_BT_PWR, [9:8] BACKUP_BUS_PMS_CONSTRAIN_APB_ADC, [7:6] BACKUP_BUS_PMS_CONSTRAIN_CRYPTO_DMA, [5:4] BACKUP_BUS_PMS_CONSTRAIN_CRYPTO_PERI, [3:2] BACKUP_BUS_PMS_CONSTRAIN_USB_WRAP
0x160 BACKUP_BUS_PMS_MONITOR_0 — SENSITIVE_BACKUP_BUS_PMS_MONITOR_0_REG
  [0] BACKUP_BUS_PMS_MONITOR_LOCK
0x164 BACKUP_BUS_PMS_MONITOR_1 reset 0x3 — SENSITIVE_BACKUP_BUS_PMS_MONITOR_1_REG
  [1] BACKUP_BUS_PMS_MONITOR_VIOLATE_EN, [0] BACKUP_BUS_PMS_MONITOR_VIOLATE_CLR
0x168 BACKUP_BUS_PMS_MONITOR_2 ro — SENSITIVE_BACKUP_BUS_PMS_MONITOR_2_REG
  [6] BACKUP_BUS_PMS_MONITOR_VIOLATE_STATUS_HWRITE, [5:3] BACKUP_BUS_PMS_MONITOR_VIOLATE_STATUS_HSIZE, [2:1] BACKUP_BUS_PMS_MONITOR_VIOLATE_STATUS_HTRANS, [0] BACKUP_BUS_PMS_MONITOR_VIOLATE_INTR
0x16C BACKUP_BUS_PMS_MONITOR_3 ro — SENSITIVE_BACKUP_BUS_PMS_MONITOR_3_REG
  [31:0] BACKUP_BUS_PMS_MONITOR_VIOLATE_HADDR
0x170 CLOCK_GATE reset 0x1 — SENSITIVE_CLOCK_GATE_REG_REG
  [0] CLK_EN
0xFFC DATE reset 0x2010200 — SENSITIVE_DATE_REG
  [27:0] DATE — reg_date
